# cyt4dn register map
Vendor: Cypress Semiconductor; Series: cyt4dn; File version: 1.0
CPU: CM7 r0p1, little endian, MPU, FPU, VTOR, 3 interrupt priority bits
Registers are 32-bit, read-write, reset 0x0 unless marked. A register's access mark holds for its fields unless they carry their own. Offsets are from the block's base; [hi:lo] are bit positions; lines under a group give offsets from that group; {n}, {i} and the like mark numbered series; 'fields as' and 'values as' point back to an identical list.

## VIDEOSS0 (part 1 of 18) — Video and Graphics Subsystem IP
Base 0x40A00000
0x00 SUBSS group — Sub Interface
  0x00 VIDEOSSCFG group — Subsystem Control.
    0x00 CTL — IP Control Register
      [31] ENABLED — VIDEOSS enable/disable bit.
        0=DIS (Disable the entire VIDEOSS. System will be held in reset until re-enabled (with the exception of the AHB interface and this register)); 1=EN (Enable VIDEOSS)
    0x04 GFX2D_CTL reset 0x80000000 — IP Control Register for Graphics 2D Core
      [31] GFX2D_ENABLED — If disabled, the Graphics 2D Core is put on reset and its clock input gated.
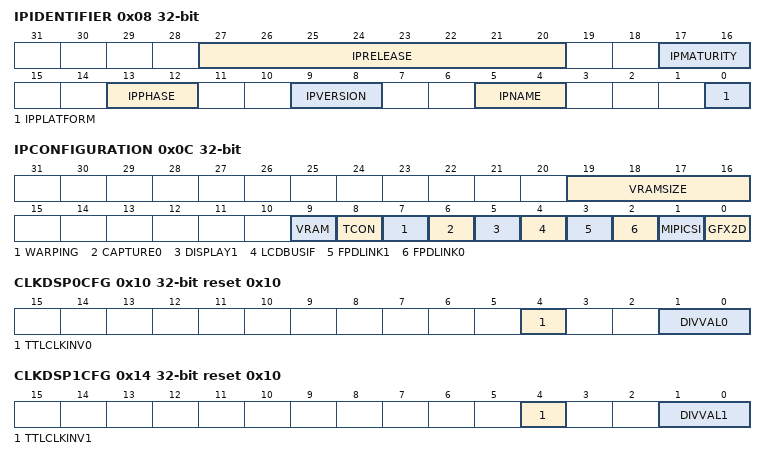
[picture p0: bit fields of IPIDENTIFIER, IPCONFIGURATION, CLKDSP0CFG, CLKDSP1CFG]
    0x08 IPIDENTIFIER ro reset not defined — IP and Design Release Identification
      [27:20] IPRELEASE — Design Release ID
      [17:16] IPMATURITY — CIC Chip Integration Cycle
        0=NONE (Pre Review); 1=CPR (CIC Physical Readiness Review); 2=CMR (CIC Mock Review); 3=CFR (CIC Final Handoff Review)
      [13:12] IPPHASE — IP Vault Phase
      [9:8] IPVERSION — IP Vault Version
      [5:4] IPNAME — Name of IP
        0=VIDEOSS (Video and Graphics Subsystem with internal SRAM); 1=VIDEOSSDDR (Video and Graphics Subsystem for external DDR-SDRAM); 2=VIDEOSSLITE (Display Composition Subsystem)
      [0] IPPLATFORM — Name of SOC Platform
        0=MXS40_S40E (MXS40 High Temperature Variant)
    0x0C IPCONFIGURATION ro reset not defined — IP Design Configuration
      [19:16] VRAMSIZE — Size of embedded Video RAM if available (in MB).
      [9] VRAM — Embedded Video RAM available (0 = no, 1 = yes)
      [8] TCON — Timing Controller available in Display Engine (0 = no, 1 = yes)
      [7] WARPING — Warping Layer available in Composition Engine (0 = no, 1 = yes)
      [6] CAPTURE0 — Capture Engine available (0 = no, 1 = yes)
      [5] DISPLAY1 — 2nd Display Engine available (0 = no, 1 = yes)
      [4] LCDBUSIF — LCD Bus Output Interface available (0 = no, 1 = yes)
      [3] FPDLINK1 — 2nd FPDLink Video Output Interface available (0 = no, 1 = yes)
      [2] FPDLINK0 — 1st FPDLink Video Output Interface available (0 = no, 1 = yes)
      [1] MIPICSI — MIPI CSI-2 Video Input Interface available (0 = no, 1 = yes)
      [0] GFX2D — Graphics 2D Core available (0 = no, 1 = yes)
    0x10 CLKDSP0CFG reset 0x10 — Display 0 Clock Configuration Register
      [4] TTLCLKINV0 — Enable bit for pixel clock inversion on TTL display output interface 0. If enabled, pixel data changes with falling instead of rising clock edge (180 deg phase shift).
      [1:0] DIVVAL0 — Clock Divider Setting (KDIV)
        0=DIV1 (No division); 1=DIV2 (Divide by 2); 2=DIV4 (Divide by 4); 3=DIV8 (Divide by 8)
    0x14 CLKDSP1CFG reset 0x10 — Display 1 Clock Configuration Register
      [4] TTLCLKINV1 — Enable bit for pixel clock inversion on TTL display output interface 1. If enabled, pixel data changes with falling instead of rising clock edge (180 deg phase shift).
      [1:0] DIVVAL1 — Clock Divider Setting (KDIV)
        values as SUBSS.VIDEOSSCFG.CLKDSP0CFG.DIVVAL0
    0x18 CAP0CFG — Capture 0 Configuration
      [1:0] CAP0SRC — Capture Source Selection
        0=TTL (TTL0 interface selected); 1=CSI (CSI-2 (DPHY) Interface Selected); 2=DSP0 (N/A); 3=DSP1 (N/A)
    0x1C FPDLINKCFG — FPDLink Configuration
      [0] FPDLINKSEL — Selects the channel mode for the two FPDlink interfaces.
        0=SINGLE (FPDlink 0 and 1 are operating independently, driven by the two Display Engine 0 and 1.); 1=DUAL (FPDlink 0 and 1 are operating synchronously, both driven by Display Engine 0.)
    0x20 DSP0_CTL — Enable for Display Engine 0
      [31] DSP0_ENABLED — This field, along with CTL.ENABLED above which enables the whole videoss IP, controls the clock and reset release of the DSP0 clock domain.
    0x24 DSP1_CTL — Enable for Display Engine 1
      [31] DSP1_ENABLED — This field, along with CTL.ENABLED above which enables the whole videoss IP, controls the clock and reset release of the DSP1 clock domain.
  0x400 VRAM group — Video RAM.
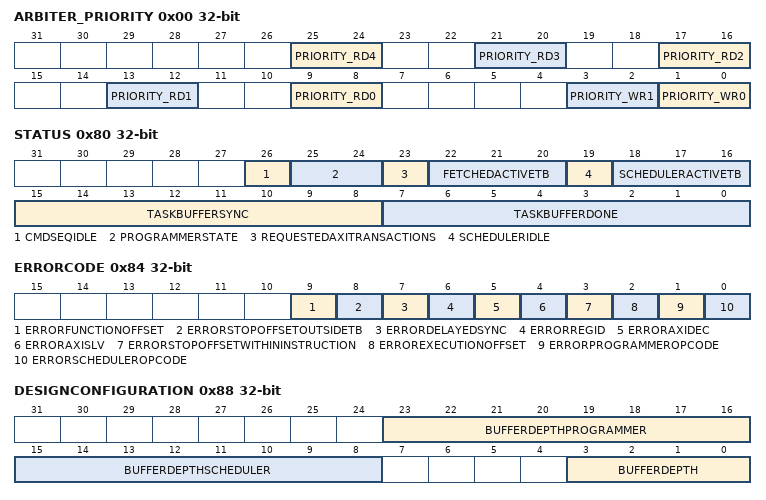
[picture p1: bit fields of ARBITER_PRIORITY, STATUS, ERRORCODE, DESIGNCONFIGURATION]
    0x00 ARBITER_PRIORITY
      [4n+9:4n+8] PRIORITY_RD{n} (n=0..4) — Priority for read slave interface {n}.
      [3:2] PRIORITY_WR1 — Priority for write slave interfaces 1.
      [1:0] PRIORITY_WR0 — Priority for write slave interfaces 0.
  0x40000 GFX2D group — Graphics 2D Core
    0x00 GFX2DCFG group — Graphics 2D Core config
      0x20 INTR_GFX2D — Interrupt cause register
        [23:0] INTR_GFX2D — Interrupt status vector. A bit is set when the related event occurs or the corresponding bit of INTR_GFX2D_SET is written. By writing 1 the corresponding bit is cleared.
      0x24 INTR_GFX2D_SET wo reset not defined — Interrupt set register
        [23:0] INTR_GFX2D_SET — Interrupt set vector. Writing a 1 to this field sets the corresponding bit of INTR_GFX2D.
      0x28 INTR_GFX2D_MASK — Interrupt mask register
        [23:0] INTR_GFX2D_MASK — Interrupt mask vector. Please note that this enable vector does not affect the INTR0 register field. It only affects INTR_GFX2D_MASKED.
      0x2C INTR_GFX2D_MASKED ro reset not defined — Interrupt masked register
        [23:0] INTR_GFX2D_MASKED — Status vector that generates the interrupt to the CPU if at least one bit of this field is set. This field corresponds to the bit-wise AND between INTR_GFX2D and INTR_GFX2D_MASK fields.
      0x30 INTR_CMDSEQ — Interrupt cause register for CmdSeq
        [21:0] INTR_CMDSEQ — Interrupt status vector. A bit is set when the related event occurs or the corresponding bit of INTR_CMDSEQ_SET is written. By writing 1 the corresponding bit is cleared.
      0x34 INTR_CMDSEQ_SET wo reset not defined — Interrupt set register
        [21:0] INTR_CMDSEQ_SET — Interrupt set vector. Writing a 1 to this field sets the corresponding bit of INTR_CMDSEQ.
      {0x40+4l} GENERALPURPOSE[{l}] (l=0..15) reset not defined — General purpose config memory
        [31:0] GENERALPURPOSE — General purpose config memory entry, does not have any function.
    0x10000 CMDSEQ group — Command Sequencer
      {0x0+0xC*l} TASKBUFFERADDRESS{l} (l=0..7) — Task buffer {l} address register
        [31:3] ADDRESSTB{l} — Task buffer {l} base address in multiple of 64-bit words.
      {0x4+0xC*l} TASKBUFFERSIZE{l} (l=0..7) — Task buffer {l} size register
        [15:0] SIZETB{l} — Task buffer {l} size in multiple of 32-bit words. The maximal size of task buffer equals to 4 * (2^16 - 1) bytes. The minimal size required to start execution is 2, because the minimal value of the stop offset is 1 and it has to be smaller then the task buffer size.
      {0x8+0xC*l} TASKBUFFERSTOPOFFSET{l} (l=0..7) — Task buffer {l} stop offset register
        [15:0] STOPOFFSETTB{l} — Task buffer {l} stop offset in multiple of 32-bit words to determine the last valid scheduling instruction. Only scheduling instructions up to this offset are executed or with other words instruction at the StopOffset-1 is the last instruction which is executed.
      {0x60+4l} TASKBUFFEREXECOFFSET{l} ro reset not defined (l=0..7) — Task buffer {l} execute offset register
        [15:0] EXECOFFSETTB{l} — Task buffer {l} execution offset in multiple of 32-bit words. Offset of the scheduling instruction that is to be executed next. Instruction at address = AddressTB{l} has offset zero.
      0x80 STATUS ro reset not defined
        [26] CMDSEQIDLE — CmdSeq is not processing any instructions and there are no outstanding AXI transactions.
        [25:24] PROGRAMMERSTATE — Execution state of programmer
          0=IDLE (When all fetched instructions have been executed and there are no functions scheduled for the execution); 1=SYNC (During execution of the SYNC instruction); 2=ACTIVE (Execution of instructions); 3=AXI_WAIT (There is function scheduled for the execution, but the internal instruction buffer is empty.)
        [23] REQUESTEDAXITRANSACTIONS — There are some outstanding axi transactions that have been requested but are not received yet.
        [22:20] FETCHEDACTIVETB — Task buffer being fetch last in programmer. If programmer is in idle state, the value of this field is not valid.
        [19] SCHEDULERIDLE — Scheduler is not processing any instructions and there are no outstanding AXI transactions.
        [18:16] SCHEDULERACTIVETB — Task buffer being executed in scheduler. If scheduler is in idle state, the value of this field is not valid.
        [15:8] TASKBUFFERSYNC — Each bit corresponds to one task buffer. '1' means that the scheduling of corresponding TB is blocked until some SW or HW state is reached.
        [7:0] TASKBUFFERDONE — Each bit corresponds to one task buffer. '1' means that the ExecOffset equals to the StopOffset
      0x84 ERRORCODE ro reset not defined — Error code register, each field of this register is one bit wide and corresponds to an error event. If the value of this register is zero, than there are no errors.
        [9] ERRORFUNCTIONOFFSET — Function offset provided by the EXEC instruction is outside of task buffer
        [8] ERRORSTOPOFFSETOUTSIDETB — Stop offset value is bigger than or equals to task buffer size. If however both are zero, no error should be raised.
        [7] ERRORDELAYEDSYNC — SYNC is following delayed SYNC in Scheduler
        [6] ERRORREGID — Error accessing an register via id that is not bound to any GPR or SPR register
        [5] ERRORAXIDEC — AXI decoder error has been occurred. SchedulerAddress and ProgrammerAddress have to be evaluated
        [4] ERRORAXISLV — AXI slave error has been occurred. SchedulerAddress and ProgrammerAddress have to be evaluated
        [3] ERRORSTOPOFFSETWITHININSTRUCTION — Stop offset is within instruction in scheduler
        [2] ERROREXECUTIONOFFSET — Execution offset is outside of the task buffer
        [1] ERRORPROGRAMMEROPCODE — Opcode error in programmer
        [0] ERRORSCHEDULEROPCODE — Opcode error in scheduler
      0x88 DESIGNCONFIGURATION ro reset not defined — Provides HW specific information.
        [23:16] BUFFERDEPTHPROGRAMMER — The buffer (axi decouple fifo) size inside of the programmer.
        [15:8] BUFFERDEPTHSCHEDULER — The buffer (axi decouple fifo) size inside of the scheduler.
        [3:0] BUFFERDEPTH — The size of the buffer between the Scheduler and the Programmer.
      0x8C SCHEDULERADDRESS ro reset not defined — Last fetched address of scheduler.
        [31:0] SCHEDULERADDRESS — Last fetched address of scheduler
      0x90 PROGRAMMERADDRESS ro reset not defined — Last fetched address of programmer.
        [31:0] PROGRAMMERADDRESS — Last fetched address of programmer
      {0x94+4l} GPR{l} ro reset not defined (l=0..15) — General purpose Register. (Internal register with id = {l})
        [31:0] GENERALPURPOSEREGISTER{l} — General Purpose Register used internally for CmdSeq and for synchronization with SW.
      0xD4 SPR0 ro reset not defined — Special Purpose Register. (Internal register with id = 16)
        [15:0] LINECOUNTERTB0 — Holds the scheduled line of the frame that is being executed in TB0. The value of this register is routed outside CmdSeq.
      {0xD4+4l} SPR{l} ro reset not defined (l=1..7) — Special Purpose Register (internal register with id = {l+16})
        [15:0] LINECOUNTERTB{l} — Holds the scheduled line of the frame that is being executed in TB{l}. The value of this register is routed outside CmdSeq.
    0x20000 BLITENG group — Blit Engine
      0x00 BLITENGCFG group — Top-Level
        0x00 STATICCONTROL
          [12] DESTINATIONPIXELMEASUREMENTEN — Enable destination pixel counting for LBO and LBO. Corresponding registers are LBODestinationPixelCounter and IBODestinationPixelCounter.
          [11] LBOSOURCEPIXELMEASUREMENTEN — Enable source pixel counting for LBO. Corresponding registers are LBOSourcePixelRGBACounter and LBOSourcePixelAlphaCounter.
          [10] TBUTILIZATIONMEASUREMENTEN — Enable utilization measurement of CmdSeq task buffers (active time for each TB). Corresponding registers are TB[x]UtilizationCounter.
          [9] LBOUTILIZATIONMEASUREMENTEN — Enable utilization measurement of LBO render mode. Corresponding registers are LBOAllFetchesActiveCounter and LBOWaitBlitEngRessourcesCounter.
          [8] BLITENGUTILIZATIONMEASUREMENTEN — Enable utilization measurement of LBO render mode. Corresponding registers are IBOCounter and LBOCounter.
          [5:4] LRSTATUSSELECT — Select pipeline from which to access status register information in line-rendering mode.
          [0] SHDEN — Enable shadowing of all RWS type registers (0=write_through, 1=shadowed). For LBO this ShdEn and ShdEn fields of all modules inside Bliteng have to be 1.
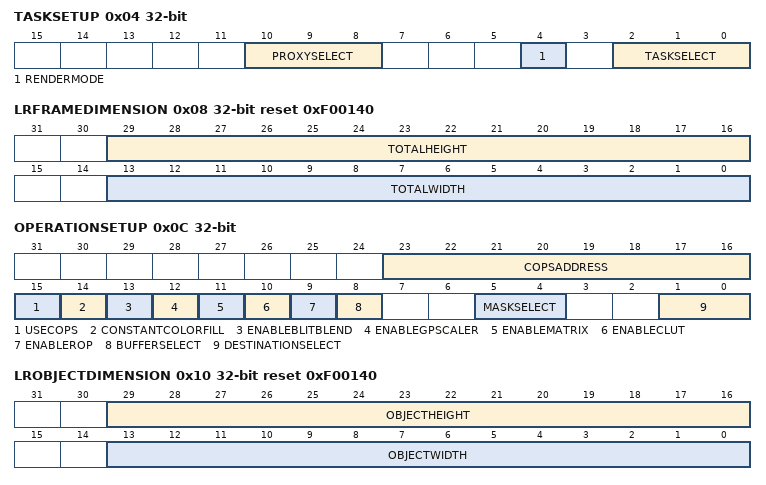
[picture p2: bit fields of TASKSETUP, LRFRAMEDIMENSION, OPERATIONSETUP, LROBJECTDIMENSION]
        0x04 TASKSETUP — Task configuration register.
          [10:8] PROXYSELECT — Proxy to use for the next operation
            0=OFF (Proxy disabled.); {v}=FETCHLBH{v-1} (Proxy connected to FETCHLBH{v-1}.) (v=1..5)
          [4] RENDERMODE — Blit engine operation mode.
            0=FRAMERENDERING (Frame rendering mode (framebuffer).); 1=LINERENDERING (Line rendering mode (linebuffer).)
          [2:0] TASKSELECT — Select task bank for operation status registers (ypos, ...).
        0x08 LRFRAMEDIMENSION reset 0xF00140 — Dimension of final frame in memory.
          [29:16] TOTALHEIGHT — Frame height (programmed with -1).
          [13:0] TOTALWIDTH — Frame width (programmed with -1).
        0x0C OPERATIONSETUP — Setup for rendering operation.
          [23:16] COPSADDRESS — Address to use in Current Object Processing State (COPS) memory (required for decode operations). Only possible in LBO mode.
          [15] USECOPS — Cops are used for the next fetch operation. If the value is zero, CopsAddress is not evaluated. Only possible in LBO mode.
          [14] CONSTANTCOLORFILL — If this field is set, the selected destination (BufferSelect) will be filled with constant color (ConstantColorRed, ConstantColorGreen, ConstantColorBlue, ConstantAlpha) not using any fetch pipeline. Only possible in LBO mode.
          [13] ENABLEBLITBLEND — Set 1 enable the BlitBlend module. If this field is set
          [12] ENABLEGPSCALER — Set 1 enable GPScaler. This field is ignored for LBO render mode.
          [11] ENABLEMATRIX — Set 1 to enable matrix.
          [10] ENABLECLUT — Set 1 to enable CLUT. This field is ignored for LBO render mode.
          [9] ENABLEROP — Set 1 to enable ROP module. This field is ignored for LBO render mode.
          [8] BUFFERSELECT — Line buffer to render into. This field is ignored for IBO render mode.
            0=RGBA (RGBA buffer.); 1=MASK (MASK buffer.)
          [5:4] MASKSELECT — Select operation for mask buffer. In IBO the buffer is provided via the FETCHMASK; in LBO the buffer is provided via internal ALPHA slice buffer. If the value of both fields this and DestinationSelect is BLEND, OFF is used for this field.
            0=OFF (Mask buffer is not read.); 1=ROP (Mask is connected to raster operation block (secondary). Only possible in IBO mode.); 2=BLEND (Mask is connected to blend operation block. Only possible in LBO mode.); 3=FETCHSRC (Mask is connected to the fetch SRC.)
          [1:0] DESTINATIONSELECT — Select operation for destination buffer. In IBO the buffer is provided via the FETCHDST in LBO the buffer is provided via internal RGBA slice buffer.
            0=OFF (Destination buffer is not read, used for FILL or COPY operations.); 1=ROP (Destination is connected to raster operation block (tertary). Only possible in IBO mode.); 2=BLEND (Destination is connected to blend operation block.); 3=FETCHMASK (Destination fetch is connected to the external input of the fetch MASK, for planar YUV. Only possible in IBO mode.)
        0x10 LROBJECTDIMENSION reset 0xF00140 — Dimension of object. Only possible in LBO mode
          [29:16] OBJECTHEIGHT — Object height (programmed with -1).
          [13:0] OBJECTWIDTH — Object width (programmed with -1).
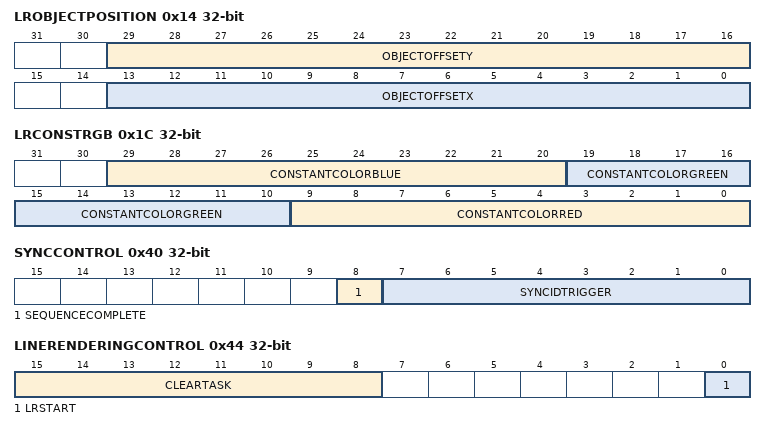
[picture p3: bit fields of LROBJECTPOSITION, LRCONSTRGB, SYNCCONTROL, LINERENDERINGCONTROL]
        0x14 LROBJECTPOSITION — Position of current object in frame coordinate system. Only possible in LBO mode
          [29:16] OBJECTOFFSETY — Object position in y direction (start at 0).
          [13:0] OBJECTOFFSETX — Object position in x direction (start at 0).
        0x18 LRCONSTALPHA — Constant alpha used to fill buffer w/o fetch unit. Has affect only if ConstantColorFill is set. Only possible in LBO mode.
          [7:0] CONSTANTALPHA — Alpha to be filled to RGBA or Alpha buffer.
        0x1C LRCONSTRGB — Constant color used to fill buffer w/o fetch unit. Has affect only if ConstantColorFill is set and BufferSelect==RGBA. Only possible in LBO mode
          [29:20] CONSTANTCOLORBLUE — Constant blue color to be filled into RGBA buffer.
          [19:10] CONSTANTCOLORGREEN — Constant green color to be filled into RGBA buffer.
          [9:0] CONSTANTCOLORRED — Constant red color to be filled into RGBA buffer.
        {0x20+4m} SYNCIDREQUEST{m} (m=0..7) — Sync ID request register.
          [31:0] SYNCIDREQUEST{m} — Sync ID requested by SW. Will be loaded into SyncIdStatus{m} if SyncIdTrigger[{m}] is set and if/once store operation is done.
        0x40 SYNCCONTROL wo reset not defined — Triggers interrupts for sequence complete of specific TB of global sequence complete interrupt.
          [8] SEQUENCECOMPLETE — Trigger SeqComplete interrupt if BlitEng is idle or the last operation has been completed.
          [7:0] SYNCIDTRIGGER — Trigger SyncIdComplete[0:7] and load SyncIdRequest[0:7] into SyncIdStatus[0:7]. Is executed after store operation is completed or no operation is active on the corresponding TB.
        0x44 LINERENDERINGCONTROL wo reset not defined — Line rendering operation control register.
          [15:8] CLEARTASK — Clear related registers (ypos, perf) of corresponding TB. Each bit corresponds to one TB.
          [0] LRSTART — Start next source to linebuffer operation.
        0x48 PERFORMANCEMEASUREMENTCONTROL wo reset not defined — Control of the performance and utilitzation measurements.
          [0] SAVEANDRESETMEASUREMENTS — All performance and utilization counters are implemented internally. Writing one to this field provides all measured values to corresponding configurations registers and resets the internal counters.
        {0x4C+4m} SYNCIDSTATUS{m} ro reset not defined (m=0..7) — Sync ID Status register for task {m}.
          [31:0] SYNCIDCOMPLETE{m} — Latest ID completed as requested by SyncIdRequest and SyncIdTrigger with TaskSelect = {m}.
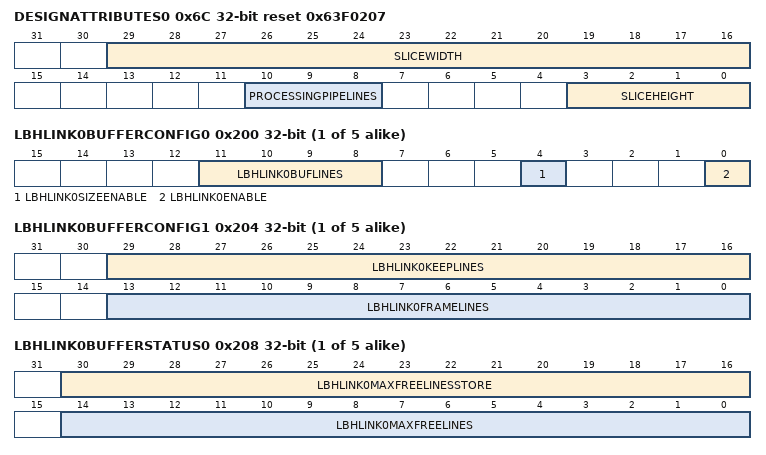
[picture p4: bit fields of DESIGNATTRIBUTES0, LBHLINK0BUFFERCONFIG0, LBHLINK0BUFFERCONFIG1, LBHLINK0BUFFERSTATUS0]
        0x6C DESIGNATTRIBUTES0 ro reset 0x63F0207 — This register contains attributes of Bliteng. They are not parameters since they cannot be easily changed, however here we still have them to provide some static status on design.
          [29:16] SLICEWIDTH — Returns the maximum width that can be rendered in LBO mode minus one.
          [10:8] PROCESSINGPIPELINES — Returns the maximum number of pixel processing pipelines LBO mode minus one.
          [3:0] SLICEHEIGHT — Returns the slice height mode minus one.
        0x70 DESIGNATTRIBUTES1 ro reset 0x63F — This register contains attributes of Bliteng. They are not parameters since they cannot be easily changed, however here we still have them to provide some static status on design.
          [13:0] GPSCALERWIDTH — Returns the maximum width that can be rendered in LBO mode minus one.
        0x74 CLOCKCOUNTER ro reset not defined — One of Clock Counter registers.
          [31:0] CLOCKCOUNTER — The internal clock counter is incremented with each 16th clock cycle if any of the measurements are activated. This field is updated with SaveAndResetMeasurements pulse and internal counter is reset.
        0x78 CLOCKCOUNTEROVERFLOW ro reset not defined — One of Clock Counter registers.
          [0] CLOCKCOUNTEROVERFLOW — This bit is set if ClockCounter overflows.
        0x7C IBOACTIVECOUNTER ro reset not defined — One of BlitEng Utilization Measurement registers.
          [31:0] IBOACTIVECOUNTER — The internal LBO counter is incremented with each 16th clock cycle when BlitEng is executing IBO operation and when BlitEngUtilizationMeasurementEn is set. This field is updated with SaveAndResetMeasurements pulse and internal counter is reset.
        0x80 LBOACTIVECOUNTER ro reset not defined — One of BlitEng Utilization Measurement registers.
          [31:0] LBOACTIVECOUNTER — The internal LBO counter is incremented with each 16th clock cycle when BlitEng is executing LBO operation and when BlitEngUtilizationMeasurementEn is set. This field is updated with SaveAndResetMeasurements pulse and internal counter is reset.
        0x84 LBOALLFETCHESACTIVECOUNTER ro reset not defined — One of the LBO utilization measurement registers.
          [31:0] LBOALLFETCHESACTIVECOUNTER — The internal counter is incremented with each 16th clock when all source fetch pipelines are active. Only active in LBO and when LBOUtilizationMeasurementEn is set. This field is updated with SaveAndResetMeasurements pulse and internal counter is reset.
        0x88 LBOWAITBLITENGRESSOURCESCOUNTER ro reset not defined — One of the LBO utilization measurement registers.
          [31:0] LBOWAITBLITENGRESSOURCESCOUNTER — The internal counter is incremented with each 16th clock when the operation has been triggered but is waiting for BlitEng ressources. Only active in LBO and when LBOUtilizationMeasurementEn is set. This field is updated with SaveAndResetMeasurements pulse and internal counter is reset.
        {0x8C+4m} TB{m}ACTIVECOUNTER ro reset not defined (m=0..7) — One of the TB utilization measurement registers. Since TB operations may be overlapping the sum of all TB utilization measurement registers may be higher than clock counter
          [31:0] TB{m}ACTIVECOUNTER — The internal counter is incremented with each 16th clock when there is any ongoing blit operation programmed via TB{m}. Only active when TBUtilizationMeasurementEn is set. This field is updated with SaveAndResetMeasurements pulse and internal counter is reset.
        0xAC LBOSOURCEPIXELRGBACOUNTER ro reset not defined — RGBA source pixel counter for LBO mode
          [31:0] LBOSOURCEPIXELRGBACOUNTER — Provides the number of processed source RGBA pixels which should be multiplied by 256. Only active in LBO and when LBOSourcePixelMeasurementEn is set. This field is updated with SaveAndResetMeasurements pulse and internal counter is reset.
        0xB0 LBOSOURCEPIXELALPHACOUNTER ro reset not defined — Alpha source pixel counter for LBO mode
          [31:0] LBOSOURCEPIXELALPHACOUNTER — Provides the number of processed source alpha pixels which should be multiplied by 256. Only active in LBO and when LBOSourcePixelMeasurementEn is set. This field is updated with SaveAndResetMeasurements pulse and internal counter is reset.
        0xB4 LBODESTINATIONPIXELCOUNTER ro reset not defined — Destination pixel counter for LBO mode
          [31:0] LBODESTINATIONPIXELCOUNTER — Provides the number of processed destination pixels which should be multiplied by 32. In the case of odd width this counter counts one more pixel per line compared to the actual number of pixels. Only active in LBO and when DestinationPixelMeasurementEn is set. This field is updated with SaveAndResetMeasurements pulse and internal counter is reset.
        0xB8 IBODESTINATIONPIXELCOUNTER ro reset not defined — Destination pixel counter for IBO mode
          [31:0] IBODESTINATIONPIXELCOUNTER — Provides the number of processed destination pixels which should be multiplied by 16. Only active in IBO and when DestinationPixelMeasurementEn is set. This field is updated with SaveAndResetMeasurements pulse and internal counter is reset.
        {0x200+0x40*m} LBHLINK{m}BUFFERCONFIG0 (m=0..4) — Line buffer configuration register 0.
          [11:8] LBHLINK{m}BUFLINES — The number of lines in the line buffer in power of two. Max supported number of lines in ringbuffer is 16384 (14pow2=16384). Programming 15 results also in 16384 lines.
          [4] LBHLINK{m}SIZEENABLE — Activates the ring buffer usage. This signal will be provided to the fetch and the store.
          [0] LBHLINK{m}ENABLE — Activates the line-buffer handshake, i.e. will stall the store or the display fetch upon respective condition.
        {0x204+0x40*m} LBHLINK{m}BUFFERCONFIG1 (m=0..4) — Line buffer configuration register 1.
          [29:16] LBHLINK{m}KEEPLINES — Number of lines to keep in the line buffer even if the display fetch is already beyond this line. Required for re-sampling operations that span over several input lines.
          [13:0] LBHLINK{m}FRAMELINES — Height of the frame in number of lines. The height must be identical to the related Blit and Composition Engine setups.
        {0x208+0x40*m} LBHLINK{m}BUFFERSTATUS0 (m=0..4) — Buffer status register 0 for the line buffer handshake. Writing to this register has no effect, reading provides the value and simultaneously resets the internal register. The value provided after the first read or if LBH is inactive is not valid.
          [30:16] LBHLINK{m}MAXFREELINESSTORE — The maximal number of free lines in the line buffer that can be written by the store.
          [14:0] LBHLINK{m}MAXFREELINES — The maximal number of free lines in the line buffer that can be scheduled by CmdSeq.
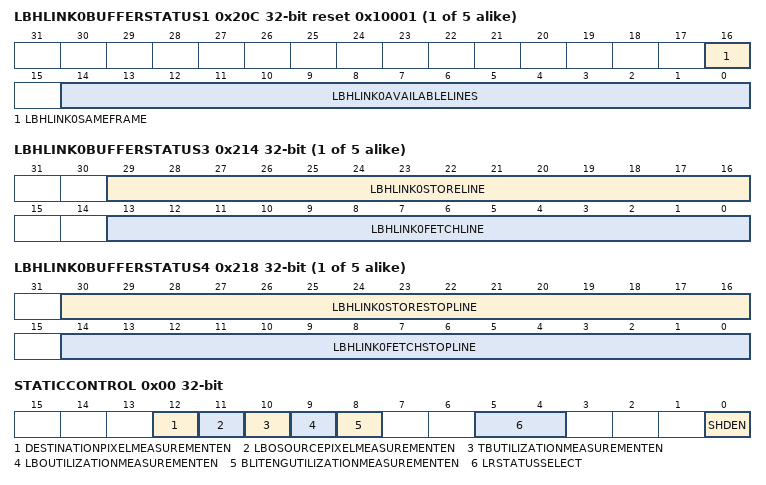
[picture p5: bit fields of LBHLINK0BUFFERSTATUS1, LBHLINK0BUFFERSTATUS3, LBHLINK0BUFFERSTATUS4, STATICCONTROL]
        {0x20C+0x40*m} LBHLINK{m}BUFFERSTATUS1 ro reset 0x10001 (m=0..4) — Buffer status register 1 for the line buffer handshake.
          [16] LBHLINK{m}SAMEFRAME — This status bit indicates if the fetch and the store are processing the same frame. If this bit is zero the store has already switched to the next frame
          [14:0] LBHLINK{m}AVAILABLELINES — The number of lines in the line buffer that the store can write.
        {0x214+0x40*m} LBHLINK{m}BUFFERSTATUS3 ro reset not defined (m=0..4) — Buffer status register 3 for the line buffer handshake.
          [29:16] LBHLINK{m}STORELINE — This field describes the line currently written by the store.
          [13:0] LBHLINK{m}FETCHLINE — This field describes the line currently read by the display fetch.
        {0x218+0x40*m} LBHLINK{m}BUFFERSTATUS4 ro reset not defined (m=0..4) — Buffer status register 4 for the line buffer handshake.
          [30:16] LBHLINK{m}STORESTOPLINE — This field describes the stopline of the store.
          [14:0] LBHLINK{m}FETCHSTOPLINE — This field describes the stopline of the display fetch.
        {0x2000+4m} PALETTE[{m}] (m=0..2047) reset not defined — Shared Palette Memory.
          [23:0] PALETTEENTRY — Shared palette entry with 24-bit. Color format can be defined by Fetch configuration.
      0x4000 FETCHSRC group
        0x00 STATICCONTROL — Common static control options.
          [23:16] BASEADDRESSAUTOUPDATE — Enable flag for continuous shadow load of BaseAddress field for each layer (layer index = bit index). When set to 1 the active BaseAddress configuration is loaded from shadow at start of each frame. This update is then executed independently from other RWS type fields. ShdEn must be enabled for this mode. When the flag is enabled for layer 0, also the FieldId0 shadow is automatically loaded.
          [0] SHDEN — Enables shadowing of all RWS type registers (0=write_through, 1=shadowed).
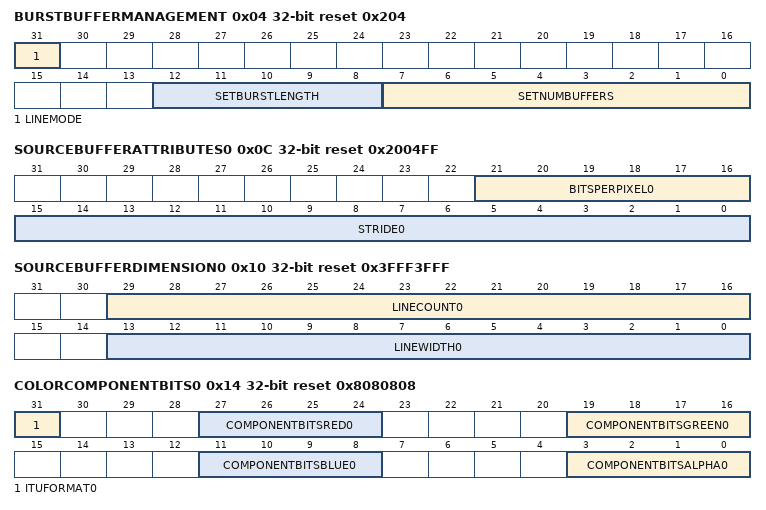
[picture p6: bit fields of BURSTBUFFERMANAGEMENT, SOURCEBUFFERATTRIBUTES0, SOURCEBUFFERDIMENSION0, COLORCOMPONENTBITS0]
        0x04 BURSTBUFFERMANAGEMENT reset 0x204 — AXI interface buffer management register
          [31] LINEMODE — Fetch buffer cache control.
            0=DISPLAY (Mandatory setting for operation in the Display Controller. Works also for Blit Engine with marginal performance impact.); 1=BLIT (Recommended setting for operation in the Blit Engine.)
          [12:8] SETBURSTLENGTH — Set this to the burst length that should be used on the AXI interface. SetNumBuffers * SetBurstLength has to be smaller or equal to ManagedBurstBuffers * BurstLengthForMaxBuffers and that bursts larger than 16 are not possible on the axi interface. Only a power of two may be specified as burst length.
          [7:0] SETNUMBUFFERS — Set this to the number of bursts that should be buffered. SetNumBuffers has to be smaller or equal to ManagedBurstBuffers and SetNumBuffers * SetBurstLength has to be smaller or equal to ManagedBurstBuffers * BurstLengthForMaxBuffers. Must be a power of 2. The minimum allowed settings is 4 except for the FetchEco derivate which has a minimum allowed setting of 2.
        0x08 BASEADDRESS0 — Source buffer base address of layer 0.
          [31:0] BASEADDRESS0 — Byte aligned start address of the layer source buffer. For a pixel width of 32 bits or DECODE operations BaseAddress bits 1 downto 0 have to be 0 and for a pixel width of 16 bit BaseAddress[0] has to be 0.
        0x0C SOURCEBUFFERATTRIBUTES0 reset 0x2004FF — Source buffer attributes for layer 0.
          [21:16] BITSPERPIXEL0 — Number of bits per pixel in the source buffer. Must be 1, 2, 4, 8, 16, 18, 24 or 32. [Exception] FetchEco does not support 18 and 24.
          [15:0] STRIDE0 — Source buffer stride of the layer in bytes minus one, used for address generation. For a pixel width of 32 bits Stride has to be dividable by 4 and given minus one and for a pixel width of 16 bit Stride has to be dividable by two and given minus one.
        0x10 SOURCEBUFFERDIMENSION0 reset 0x3FFF3FFF — Source buffer dimension of layer 0.
          [29:16] LINECOUNT0 — Number of lines of the source buffer of the layer minus one.
          [13:0] LINEWIDTH0 — Width of the source buffer of the layer in pixels minus one.
        0x14 COLORCOMPONENTBITS0 reset 0x8080808 — Size of color components for RGB, YUV and index formats (layer 0).
          [31] ITUFORMAT0 — When ComponentBitsRed/Green/Blue is set to 10 and this mode enabled (value 1), then input format is considered 8.2 instead of 10.0 bits (max color is 1020 instead of 1023). This is compliant to ITU 656 standard.
          [27:24] COMPONENTBITSRED0 — Red, Y (luma) and palette index.
          [19:16] COMPONENTBITSGREEN0 — Green and U (chroma).
          [11:8] COMPONENTBITSBLUE0 — Blue and V (chroma).
          [3:0] COMPONENTBITSALPHA0 — Alpha.
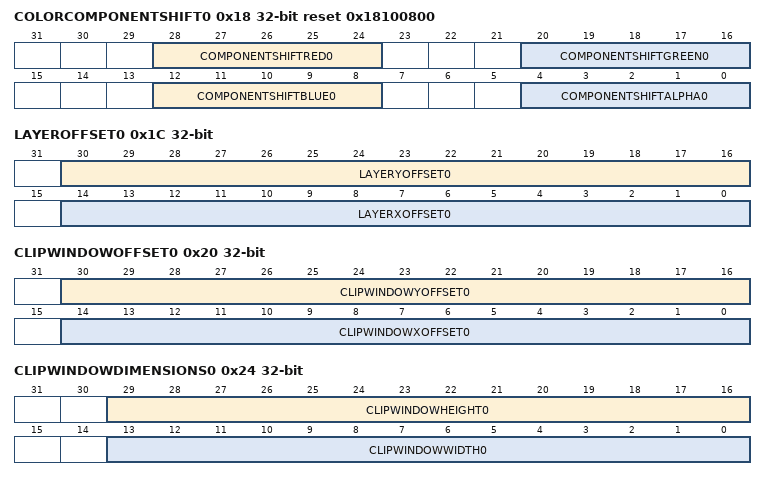
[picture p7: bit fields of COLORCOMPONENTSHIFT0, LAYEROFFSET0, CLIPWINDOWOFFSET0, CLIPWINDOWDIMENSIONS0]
        0x18 COLORCOMPONENTSHIFT0 reset 0x18100800 — Bit position of color components for RGB, YUV and index formats (layer 0).
          [28:24] COMPONENTSHIFTRED0 — Red, Y (luma) and palette index.
          [20:16] COMPONENTSHIFTGREEN0 — Green and U (chroma).
          [12:8] COMPONENTSHIFTBLUE0 — Blue and V (chroma).
          [4:0] COMPONENTSHIFTALPHA0 — Alpha.
        0x1C LAYEROFFSET0 — Position of layer 0 within the destination frame.
          [30:16] LAYERYOFFSET0 — Vertical offset (Y). (format is signed integer)
          [14:0] LAYERXOFFSET0 — Horizontal offset (X). (format is signed integer)
        0x20 CLIPWINDOWOFFSET0 — Clip window position for layer 0.
          [30:16] CLIPWINDOWYOFFSET0 — Vertical position (Y). (format is signed integer)
          [14:0] CLIPWINDOWXOFFSET0 — Horizontal position (X). (format is signed integer)
        0x24 CLIPWINDOWDIMENSIONS0 — Clip window size for layer 0.
          [29:16] CLIPWINDOWHEIGHT0 — Height.
          [13:0] CLIPWINDOWWIDTH0 — Width.
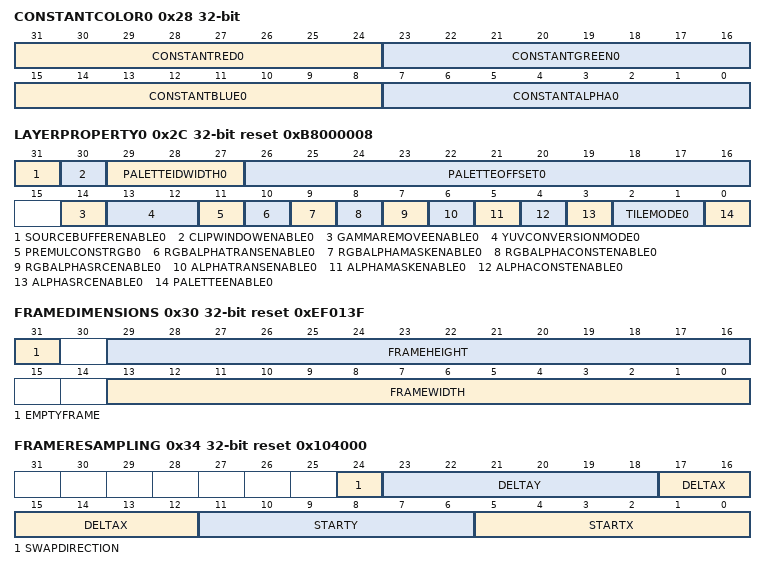
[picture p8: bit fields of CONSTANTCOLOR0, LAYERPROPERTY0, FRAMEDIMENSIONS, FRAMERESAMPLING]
        0x28 CONSTANTCOLOR0 — Constant color for layer 0.
          [31:24] CONSTANTRED0 — Red and Y (luma).
          [23:16] CONSTANTGREEN0 — Green and U (chroma).
          [15:8] CONSTANTBLUE0 — Blue and V (chroma).
          [7:0] CONSTANTALPHA0 — Alpha.
        0x2C LAYERPROPERTY0 reset 0xB8000008 — Common properties of layer 0.
          [31] SOURCEBUFFERENABLE0 — Value 1 enables the source buffer for this layer. When disabled the tiling color is used only (TileMode TILE_PAD not allowed).
          [30] CLIPWINDOWENABLE0 — Value 1 enables the clip window for this layer. Pixels outside the clip window get the clip color, pixels inside the source or tiling color.
          [29:27] PALETTEIDWIDTH0 — Number minus one of least significant bits of pixel data read from the source buffer that are used as index value for color palette look-up.
          [26:16] PALETTEOFFSET0 — Palette may contain multiple areas. This offset shows to the starting position of the currently used area.
          [14] GAMMAREMOVEENABLE0 — Value 1 enables the stage to remove a gamma from RGB components.
          [13:12] YUVCONVERSIONMODE0 — Enables different kind of YUV to RGB conversions.
            0=OFF (No conversion.); 1=ITU601 (Conversion from YCbCr (YUV) to RGB according to ITU recommendation BT.601-6 (standard definition TV). Input range is 16..235 for Y and 16..240 for U/V.); 2=ITU601_FR (Conversion from YCbCr (YUV) to RGB according to ITU recommendation BT.601-6, but assuming full range YUV inputs (0..255). Most typically used for computer graphics (e.g. for JPEG encoding).); 3=ITU709 (Conversion from YCbCr (YUV) to RGB according to ITU recommendation BT.709-5 part 2 (high definition TV). Input range is 16..235 for Y and 16..240 for U/V.)
          [11] PREMULCONSTRGB0 — When enabled (value 1) the values given by ConstantRed/Green/Blue are used instead of alpha for source RGB pre-multiply. Settings RGBAlphaSrc/Const/Mask/TransEnable have no effect then.
          [10] RGBALPHATRANSENABLE0 — Value 1 enables transparent alpha (0 or 1 depending on RGB matching ConstantColor setting) for RGB pre-multiply. When disabled transparent alpha is set to 1.
          [9] RGBALPHAMASKENABLE0 — Value 1 enables mask alpha (read by another Fetch unit from a separate alpha layer) for RGB pre-multiply. When disabled mask alpha is set to 1. Alpha mask input must be enabled for this field to have effect.
          [8] RGBALPHACONSTENABLE0 — Value 1 enables constant alpha (ConstAlpha fields) for RGB pre-multiply. When disabled constant alpha is set to 1.
          [7] RGBALPHASRCENABLE0 — Value 1 enables source alpha (stored together with color component in the source buffer) for RGB pre-multiply. When disabled source alpha is set to 1.
          [6] ALPHATRANSENABLE0 — Value 1 enables transparent alpha for computing the output alpha. When disabled transparent alpha is set to 1.
          [5] ALPHAMASKENABLE0 — Value 1 enables mask alpha for computing the output alpha. When disabled mask alpha is set to 1.
          [4] ALPHACONSTENABLE0 — Value 1 enables constant alpha for computing the output alpha. When disabled constant alpha is set to 1.
          [3] ALPHASRCENABLE0 — Value 1 enables source alpha for computing the output alpha. When disabled source alpha is set to 1.
          [2:1] TILEMODE0 — Select the tile mode for pixels outside the source buffer. Clip color (0,0,0,0) takes precedence if a pixel becomes subject to both tiling and clipping.
            0=TILE_FILL_ZERO (Use zero value); 1=TILE_FILL_CONSTANT (Use constant color register value); 2=TILE_PAD (Use closest pixel from source buffer. Must not be used for DECODE or YUV422 operations or when SourceBufferEnable is 0.); 3=TILE_PAD_ZERO (Use closest pixel from source buffer but zero for alpha component. Must not be used for DECODE or YUV422 operations or when SourceBufferEnable is 0.)
          [0] PALETTEENABLE0 — Enables (value = 1) a color palette with 8 bits input and 24 bits output. Lower bits of the lookup index are read from memory (PaletteIdWidth0), upper bits are set to index of this layer. Palette output is extended by upper bits of index word read from memory (e.g. to store alpha together with index). Result is mapped to color channels according to ColorComponentBits/Shift settings.
        0x30 FRAMEDIMENSIONS reset 0xEF013F — Output frame dimension.
          [31] EMPTYFRAME — When enabled output frame is empty. FrameWidth/Height settings have no effect then. Can be used to load shadows or to generate synchronization signals only (frame/sequence complete). If enabled, InputSelect must be set to INACTIVE.
          [29:16] FRAMEHEIGHT — Frame height minus one.
          [13:0] FRAMEWIDTH — Frame width minus one.
        0x34 FRAMERESAMPLING reset 0x104000 — Resampling options for output frame.
          [24] SWAPDIRECTION — Swaps X and Y directions for re-sampling. When enabled (= 1) DeltaY is applied for horizontal and DeltaX for vertical step on destination frame.
          [23:18] DELTAY — Increment of Y coordinate for vertical step in destination frame. (format is signed fix-point 4.2)
          [17:12] DELTAX — Increment of X coordinate for horizontal step in destination frame. (format is signed fix-point 4.2)
          [11:6] STARTY — Y coordinate of first sample point relative to origin. (format is signed fix-point 4.2)
          [5:0] STARTX — X coordinate of first sample point relative to origin. (format is signed fix-point 4.2)
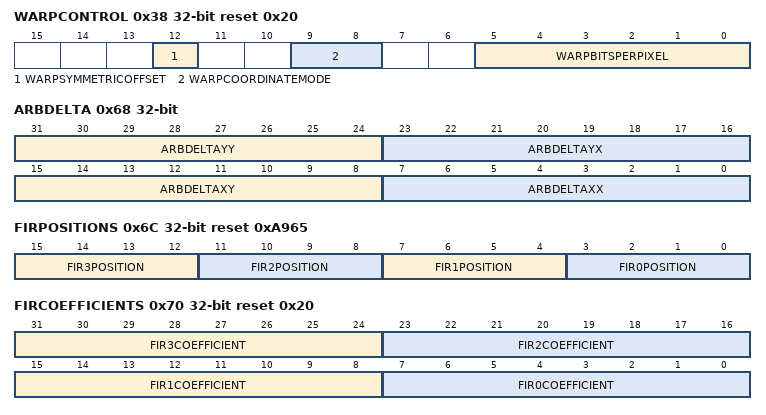
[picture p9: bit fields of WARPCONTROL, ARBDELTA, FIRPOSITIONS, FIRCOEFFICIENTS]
        0x38 WARPCONTROL reset 0x20 — Warping control options.
          [12] WARPSYMMETRICOFFSET — Value 1 enables symmetric range for negative and positive coordinate values by adding an offset of +0.03125 internally to all coordinate input values. Recommended for small coordinate formats in DD_PNT mode.
          [9:8] WARPCOORDINATEMODE — Content of pixel data in the coordinate layer.
            0=PNT (x and y (sample points).); 1=D_PNT (dx and dy (vectors between adjacent sample points).); 2=DD_PNT (ddx and ddy (deltas between adjacent vectors).)
          [5:0] WARPBITSPERPIXEL — Number of bits per pixel in the coordinate layer, which is read by another Fetch unit. Has to be 1, 2, 4, 8, 16 or 32.
        0x3C PERSPSTARTX — Start value X for affine/perspective warping.
          [31:0] PERSPSTARTX — Start value for homogenous X coordinate relative to origin. (format is floating-point 1e8m23)
        0x40 PERSPSTARTY — Start value Y for affine/perspective warping.
          [31:0] PERSPSTARTY — Start value for homogenous Y coordinate relative to origin. (format is floating-point 1e8m23)
        0x44 PERSPDELTAXX reset 0x3F800000 — DeltaXX increment for affine/perspective warping.
          [31:0] PERSPDELTAXX — Increment of homogenous X coordinate for horizontal step (X) in destination frame. (format is floating-point 1e8m23)
        0x48 PERSPDELTAYY reset 0x3F800000 — DeltaYY increment for affine/perspective warping.
          [31:0] PERSPDELTAYY — Increment of homogenous Y coordinate for vertical step (Y) in destination frame. (format is floating-point 1e8m23)
        0x4C PERSPDELTAXY — DeltaXY increment for affine/perspective warping.
          [31:0] PERSPDELTAXY — Increment of homogenous Y coordinate for horizontal step (X) in destination frame. (format is floating-point 1e8m23)
        0x50 PERSPDELTAYX — DeltaYX increment for affine/perspective warping.
          [31:0] PERSPDELTAYX — Increment of homogenous X coordinate for vertical step (Y) in destination frame. (format is floating-point 1e8m23)
        0x54 PERSPSTARTW reset 0x3F800000 — Start value W for perspective warping.
          [31:0] PERSPSTARTW — Start value for homogenous W coordinate relative to origin. (format is floating-point 1e8m23)
        0x58 PERSPDELTAXW — DeltaWX increment for perspective warping.
          [31:0] PERSPDELTAXW — Increment of homogenous W coordinate for horizontal step (X) in destination frame. (format is floating-point 1e8m23)
        0x5C PERSPDELTAYW — DeltaWY increment for perspective warping.
          [31:0] PERSPDELTAYW — Increment of homogenous W coordinate for vertical step (Y) in destination frame. (format is floating-point 1e8m23)
        0x60 ARBSTARTX — Start value X for arbitrary warping.
          [20:0] ARBSTARTX — Start point for sample-point interpolation (X coordinate). (format is signed fix-point 16.5)
        0x64 ARBSTARTY — Start value Y for arbitrary warping.
          [20:0] ARBSTARTY — Start point for sample-point interpolation (Y coordinate). (format is signed fix-point 16.5)
        0x68 ARBDELTA — Start values for delta incrementation of arbitrary warping.
          [31:24] ARBDELTAYY — Y coordinate of vector between start and first sample point. (format is signed fix-point 3.5)
          [23:16] ARBDELTAYX — X coordinate of vector between start and first sample point. (format is signed fix-point 3.5)
          [15:8] ARBDELTAXY — Y coordinate of vector between first and second sample point. (format is signed fix-point 3.5)
          [7:0] ARBDELTAXX — X coordinate of vector between first and second sample point. (format is signed fix-point 3.5)
        0x6C FIRPOSITIONS reset 0xA965 — FIR sequence control register.
          [15:12] FIR3POSITION — Position of fourth pixel.
          [11:8] FIR2POSITION — Position of third pixel.
          [7:4] FIR1POSITION — Position of second pixel.
          [3:0] FIR0POSITION — Position of first pixel.
        0x70 FIRCOEFFICIENTS reset 0x20
          [31:24] FIR3COEFFICIENT — Fourth coefficient. (format is signed fix-point 3.5)
          [23:16] FIR2COEFFICIENT — Third coefficient. (format is signed fix-point 3.5)
          [15:8] FIR1COEFFICIENT — Second coefficient. (format is signed fix-point 3.5)
          [7:0] FIR0COEFFICIENT — First coefficient. (format is signed fix-point 3.5)
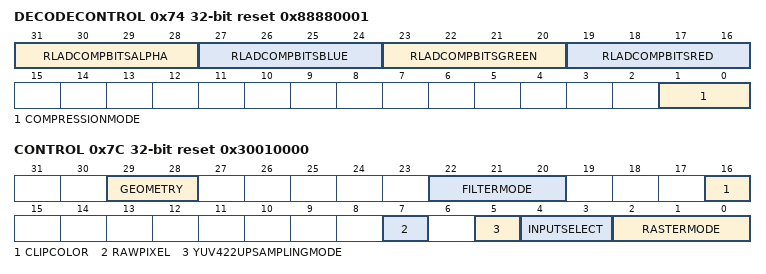
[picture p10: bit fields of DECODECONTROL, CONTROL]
        0x74 DECODECONTROL reset 0x88880001 — Control options for RLAD decompression.
          [31:28] RLADCOMPBITSALPHA — Maximum for average number of bits per compressed pixel for Alpha channel. This must match the corresponding encoder setting.
          [27:24] RLADCOMPBITSBLUE — Maximum for average number of bits per compressed pixel for Blue or V (chroma) channel. This must match the corresponding encoder setting.
          [23:20] RLADCOMPBITSGREEN — Maximum for average number of bits per compressed pixel for Green or U (chroma) channel. This must match the corresponding encoder setting.
          [19:16] RLADCOMPBITSRED — Maximum for average number of bits per compressed pixel for Red or Y (luma) channel. This must match the corresponding encoder setting.
          [1:0] COMPRESSIONMODE — Algorithm that the encoder used for compression.
            0=RLAD (Run-Length Adaptive Dithering (lossy compression).); 1=RLAD_UNIFORM (Run-Length Adaptive Dithering (lossy compression; uniform package size).); 2=RLA (Run-Length Adaptive (lossless compression).); 3=RL (Standard Run-Length. In contrary to other modes is in big endian format.)
        0x78 SOURCEBUFFERLENGTH — Source buffer length for compressed data.
          [28:0] RLEWORDS — Number of 32-bit words minus one that are required to decode the run length encoded source buffer.
        0x7C CONTROL reset 0x30010000 — Shared common control settings for all layers.
          [29:28] GEOMETRY — Control the geomety settings (PerspStartX/Y/W and PerspDeltaXX/XY/YX/YY/XW/YW usage) for the raster mode PERSPECTIVE.
            0=TRANSLATE (PerspStartX/Y are used. (PerspDeltaXY/YX/XW/YW are 0. PerspDeltaXX/YY and PerspStartW are 1.)); 1=SCALE (PerspStartX/Y and PerspDeltaXX/YY are used. (PerspDeltaXY/YX/XW/YW are 0. PerspStartW is 1.)); 2=ROTATION (PerspStartX/Y and PerspDeltaXX/XY/YX/YY are used. (PerspDeltaXW/YW are 0. PerspStartW is 1.)); 3=PERSPECTIVE (All values PerspStartX/Y/W and PerspDeltaXX/XY/YX/YY/XW/YW are used)
          [22:20] FILTERMODE — Use this to select between nearest and bilinear filtering. Only has an effect if rastermode == ARBITRARY or rastermode == PERSPECTIVE or rastermode == AFFINE.
            0=NEAREST (Chooses pixel closest to sample point); 1=BILINEAR (Calculates result from 4 pixels closest to sample point); 2=FIR2 (FIR mode with 2 programmable pixel positions and coefficients); 3=FIR4 (FIR mode with 4 programmable pixel positions and coefficients); 4=HOR_LINEAR (Calculates result from 2 pixels closest to the sample point and on the same line)
          [16] CLIPCOLOR — Selects which color to take for pixels that do not lie inside the clip window of any layer.
            0=NULL (Null color.); 1=LAYER (Color of layer number given by ClipLayer (or layer 0 when Fetch unit has one layer only). The color is then the layer's source or tiling color.)
          [7] RAWPIXEL — Raw pixel mode. If enabled (value = 1), the ComponentBits/Shift settings are replaced for all layers by fixed values that allow passing the pixel data read from memory unchanged to subsequent units (e.g. for reading coordinate layers). Multiply stages and transparent color are deactivated. Skip and Tile pixels are not affected by this setting.
          [5] YUV422UPSAMPLINGMODE — Selects a method for horizontal up-sampling of YUV 422/420 input data.
            0=REPLICATE (Replicate mode for interspersed samples (UV samples between Y samples).); 1=INTERPOLATE (Interpolate mode for coaligned samples (UV samples at Y sample positions).)
          [4:3] INPUTSELECT — Selects function for the frame input port.
            0=INACTIVE (Not used.); 1=COMPPACK (Used for component packing (e.g. UV or source alpha buffer).); 2=ALPHAMASK (Used for RGB and alpha pre-multiply stage (mask alpha buffer).); 3=COORDINATE (Used for arbitrary warping (coordinate buffer).)
          [2:0] RASTERMODE — Selects a method how to generate source buffer sample points.
            0=NORMAL ([IBO only, for LBO use PERSPECTIVE with corresponding Geometry] First sample at StartX/Y relative to origin. Hor/ver increments using DeltaX/Y and DeltaSwap setup.); 1=DECODE ([FetchDecode/FetchBlit only] Source buffer is an encoded bit stream. First sample at origin (0,0). Hor/ver increments = (1,0)/(0,1).); 2=ARBITRARY ([FetchBlit/Warp only] Arbitrary warping (filter is active). Coordinates are read from frame input port. InputSelect must be set to COORDINATE. ArbStartX/Y and ArbDeltaXX/XY/YX/YY must be setup.); 3=PERSPECTIVE ([FetchBlit only] Affine/Perspective warping (filter is active). First sample at PerspStartX/Y/W. Hor/ver increments using PerspDeltaXX/XY/YX/YY/WX/WY. Homogeneous coordinates. See also field Geometry to reduce coordinate amount.); 4=YUV422 ([FetchBlit/Decode only] Source buffer is packed YUV 422. First sample at origin (0,0). Hor/ver increments = (1,0)/(0,1). All correllated window widths and horizontal offsets must be even.)

## Notices in the file
Copyright 2016-2019, Cypress Semiconductor Corporation.  All rights reserved.
You may use this file only in accordance with the license, terms, conditions,
disclaimers, and limitations in the end user license agreement accompanying
the software package with which this file was provided.
